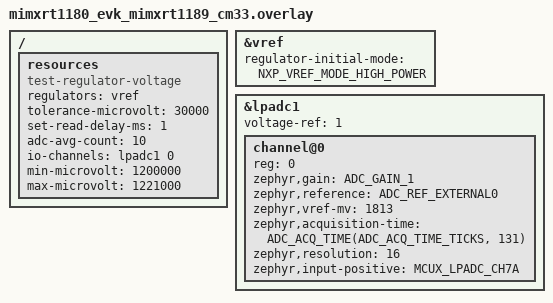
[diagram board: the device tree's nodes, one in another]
/*
 * Copyright 2025 NXP
 * SPDX-License-Identifier: Apache-2.0
 */

#include <zephyr/dt-bindings/adc/adc.h>
#include <zephyr/dt-bindings/adc/mcux-lpadc.h>
#include <zephyr/dt-bindings/regulator/nxp_vref.h>

/ {
	resources: resources {
		compatible = "test-regulator-voltage";
		regulators = <&vref>;
		tolerance-microvolt = <30000>;
		set-read-delay-ms = <1>;
		adc-avg-count = <10>;
		io-channels = <&lpadc1 0>;
		min-microvolt = <1200000>;
		max-microvolt = <1221000>;
	};
};

&vref {
	regulator-initial-mode = <NXP_VREF_MODE_HIGH_POWER>;
};

&lpadc1 {
	#address-cells = <1>;
	#size-cells = <0>;

	voltage-ref = <1>;

	channel@0 {
		reg = <0>;
		zephyr,gain = "ADC_GAIN_1";
		zephyr,reference = "ADC_REF_EXTERNAL0";
		/* VDDA_ADC_1P8 is not accurate to 1800mV, after measurement,
		 * the actual voltage is 1813mV.
		 */
		zephyr,vref-mv = <1813>;
		zephyr,acquisition-time = <ADC_ACQ_TIME(ADC_ACQ_TIME_TICKS, 131)>;
		zephyr,resolution = <16>;
		zephyr,input-positive = <MCUX_LPADC_CH7A>;
	};
};
